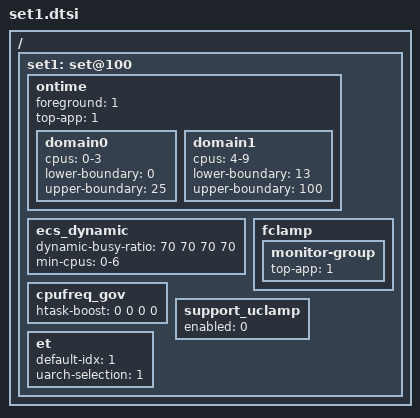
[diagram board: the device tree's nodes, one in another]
/ {
	/* power-scenario mode - default */
	set1: set@100 {
		/* Ontime Migration */
		ontime {
			foreground 	= <1>;
			top-app		= <1>;

			domain0 {
				cpus = "0-3";
				lower-boundary = <0>;
				upper-boundary = <25>;
			};
			domain1 {
				cpus = "4-9";
				lower-boundary = <13>;
				upper-boundary = <100>;
			};
		};

		ecs_dynamic {
			dynamic-busy-ratio = <70 70 70 70>;
			min-cpus = "0-6";
		};

		fclamp {
			monitor-group {
				top-app         = <1>;
			};
		};

		cpufreq_gov {
				/* LIT MED-L MED-H BIG */
			htask-boost = < 0 0 0 0>;	/* disable heavy task boost */
		};

		support_uclamp {
			enabled = <0>;
		};

		et {
			default-idx = < 1 >;
			uarch-selection = < 1 >;
		};
	};
};
